AUTOSAR XML (schema 00048)
package /VehicleProject
  system System
package /Cluster
  can cluster CAN00: protocol-name=CAN  # CANFD364
    can physical channel CHNL: comm-connectors=CN_CAN00
      frame msg_MyECU_Lamp_oCAN00: id 0x511, from MyECU, frame-length=32, can-addressing-mode=STANDARD, can-frame-rx-behavior=ANY, can-frame-tx-behavior=CAN-FD  # Motor FOC diagnostic data. MotorFoc_Page selects Control (0xA0), PWM (0xA1), or ADC (0xA2) payload.
        multiplexed i pdu msg_MyECU_Lamp_oCAN00:
          length=32
          dynamic-part{segment-positions=[{segment-byte-order=little-endian, segment-length=32, segment-position=0}, {segment-byte-order=little-endian, segment-length=208, segment-position=48}], dynamic-part-alternatives=[{i-pdu=msg_MyECU_Lamp_MxA0_oCAN00, initial-dynamic-part=true, selector-field-code=160}, {i-pdu=msg_MyECU_Lamp_MxA1_oCAN00, initial-dynamic-part=false, selector-field-code=161}, {i-pdu=msg_MyECU_Lamp_MxA2_oCAN00, initial-dynamic-part=false, selector-field-code=162}]}
          selector-field-byte-order=little-endian
          selector-field-length=8
          selector-field-start-position=0
          static-part{segment-position{segment-byte-order=little-endian, segment-length=16, segment-position=32}, i-pdu=msg_MyECU_Lamp_Mx_oCAN00}
          unused-bit-pattern=0
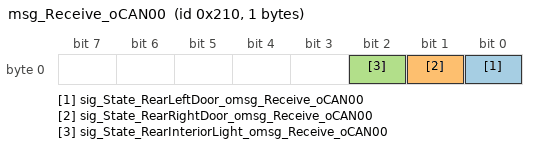
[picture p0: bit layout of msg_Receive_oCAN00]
      frame msg_Receive_oCAN00: id 0x210, to MyECU, frame-length=1, can-addressing-mode=STANDARD, can-frame-rx-behavior=ANY, can-frame-tx-behavior=CAN-20
        pdu msg_Receive_oCAN00: length=1, minimum-delay=0, transmission-mode-false-timing=cyclic-timing={time-offset=0, time-period=0.1}, transmission-mode-true-timing=cyclic-timing={time-offset=0, time-period=0.1}, unused-bit-pattern=0
          signal sig_State_RearLeftDoor_omsg_Receive_oCAN00: start 0, 1 bit, little-endian, i-signal-type=PRIMITIVE, init-value=0, base-type=boolean, compu-method=CM_sig_State_RearLeftDoor, data-constr=DC_sig_State_RearLeftDoor, transfer-property=PENDING, to MyECU
          signal sig_State_RearRightDoor_omsg_Receive_oCAN00: start 1, 1 bit, little-endian, i-signal-type=PRIMITIVE, init-value=0, base-type=boolean, compu-method=CM_sig_State_RearRightDoor, data-constr=DC_sig_State_RearRightDoor, transfer-property=PENDING, to MyECU
          signal sig_State_RearInteriorLight_omsg_Receive_oCAN00: start 2, 1 bit, little-endian, i-signal-type=PRIMITIVE, init-value=0, base-type=boolean, compu-method=CM_sig_State_RearInteriorLight, data-constr=DC_sig_State_RearInteriorLight, transfer-property=PENDING, to MyECU
      frame msg_Transmit_oCAN00: id 0x200, from MyECU, frame-length=1, can-addressing-mode=STANDARD, can-frame-rx-behavior=ANY, can-frame-tx-behavior=CAN-20
        pdu msg_Transmit_oCAN00: length=1, minimum-delay=0, transmission-mode-false-timing=cyclic-timing={time-offset=0, time-period=0.1}, transmission-mode-true-timing=cyclic-timing={time-offset=0, time-period=0.1}, unused-bit-pattern=0
          signal sig_RearInteriorLight_omsg_Transmit_oCAN00: start 0, 1 bit, little-endian, i-signal-type=PRIMITIVE, init-value=0, base-type=boolean, compu-method=CM_sig_RearInteriorLight, data-constr=DC_sig_RearInteriorLight, transfer-property=PENDING
      pdu triggering PT_msg_MyECU_Lamp_Mx: pdu=msg_MyECU_Lamp_Mx_oCAN00, from MyECU
      pdu triggering PT_msg_MyECU_Lamp_MxA{0..2}: pdu=msg_MyECU_Lamp_MxA{0..2}_oCAN00, from MyECU
package /ECU
  ecu instance MyECU: associated-com-i-pdu-group=[MyECU_oCAN00_Rx, MyECU_oCAN00_Tx]
    can communication controller CT_CAN00
    can communication connector CN_CAN00: comm-controller=CT_CAN00
package /IPDUGroup
  i signal i pdu group MyECU_oCAN00_Rx: communication-direction=IN, i-signal-i-pdus=msg_Receive_oCAN00
  i signal i pdu group MyECU_oCAN00_Tx: communication-direction=OUT
    i-signal-i-pdus:
      msg_MyECU_Lamp_Mx_oCAN00
      msg_MyECU_Lamp_MxA{0..2}_oCAN00
      msg_Transmit_oCAN00
package /PDU
  pdu msg_MyECU_Lamp_Mx_oCAN00: length=32, minimum-delay=0, transmission-mode-true-timing=event-controlled-timing={number-of-repetitions=0, repetition-period=0}, unused-bit-pattern=0
    signal MotorFoc_Sequence_Mx_omsg_MyECU_Lamp_oCAN00: start 32, 16 bit, little-endian, i-signal-type=PRIMITIVE, init-value=0, base-type=uint16, compu-method=CM_MotorFoc_Sequence, data-constr=DC_MotorFoc_Sequence, transfer-property=TRIGGERED-WITHOUT-REPETITION
  pdu msg_MyECU_Lamp_MxA0_oCAN00: length=32, minimum-delay=0, transmission-mode-true-timing=cyclic-timing={time-offset=0, time-period=0.015}, unused-bit-pattern=0
    signal MotorFoc_Page_MxA0_omsg_MyECU_Lamp_oCAN00: start 0, 8 bit, little-endian, i-signal-type=PRIMITIVE, init-value=160, base-type=uint8, compu-method=CM_MotorFoc_Page, data-constr=DC_MotorFoc_Page, transfer-property=PENDING
    signal MotorFoc_MotorMode_MxA0_omsg_MyECU_Lamp_oCAN00: start 8, 8 bit, little-endian, i-signal-type=PRIMITIVE, init-value=0, base-type=uint8, compu-method=CM_MotorFoc_MotorMode, data-constr=DC_MotorFoc_MotorMode, transfer-property=PENDING
    signal MotorFoc_Fault_MxA0_omsg_MyECU_Lamp_oCAN00: start 16, 8 bit, little-endian, i-signal-type=PRIMITIVE, init-value=0, base-type=uint8, compu-method=CM_MotorFoc_Fault, data-constr=DC_MotorFoc_Fault, transfer-property=PENDING
    signal MotorFoc_FaultReason_MxA0_omsg_MyECU_Lamp_oCAN00: start 24, 8 bit, little-endian, i-signal-type=PRIMITIVE, init-value=0, base-type=uint8, compu-method=CM_MotorFoc_FaultReason, data-constr=DC_MotorFoc_FaultReason, transfer-property=PENDING
    signal MotorFoc_IdRef_A_MxA0_omsg_MyECU_Lamp_oCAN00: start 48, 16 bit, little-endian, i-signal-type=PRIMITIVE, init-value=0, base-type=sint16, compu-method=CM_MotorFoc_IdRef_A, data-constr=DC_MotorFoc_IdRef_A, unit=U_A, transfer-property=PENDING
    signal MotorFoc_IqRef_A_MxA0_omsg_MyECU_Lamp_oCAN00: start 64, 16 bit, little-endian, i-signal-type=PRIMITIVE, init-value=0, base-type=sint16, compu-method=CM_MotorFoc_IqRef_A, data-constr=DC_MotorFoc_IqRef_A, unit=U_A, transfer-property=PENDING
    signal MotorFoc_Id_A_MxA0_omsg_MyECU_Lamp_oCAN00: start 80, 16 bit, little-endian, i-signal-type=PRIMITIVE, init-value=0, base-type=sint16, compu-method=CM_MotorFoc_Id_A, data-constr=DC_MotorFoc_Id_A, unit=U_A, transfer-property=PENDING
    signal MotorFoc_Iq_A_MxA0_omsg_MyECU_Lamp_oCAN00: start 96, 16 bit, little-endian, i-signal-type=PRIMITIVE, init-value=0, base-type=sint16, compu-method=CM_MotorFoc_Iq_A, data-constr=DC_MotorFoc_Iq_A, unit=U_A, transfer-property=PENDING
    signal MotorFoc_Iu_A_MxA0_omsg_MyECU_Lamp_oCAN00: start 112, 16 bit, little-endian, i-signal-type=PRIMITIVE, init-value=0, base-type=sint16, compu-method=CM_MotorFoc_Iu_A, data-constr=DC_MotorFoc_Iu_A, unit=U_A, transfer-property=PENDING
    signal MotorFoc_Iv_A_MxA0_omsg_MyECU_Lamp_oCAN00: start 128, 16 bit, little-endian, i-signal-type=PRIMITIVE, init-value=0, base-type=sint16, compu-method=CM_MotorFoc_Iv_A, data-constr=DC_MotorFoc_Iv_A, unit=U_A, transfer-property=PENDING
    signal MotorFoc_Iw_A_MxA0_omsg_MyECU_Lamp_oCAN00: start 144, 16 bit, little-endian, i-signal-type=PRIMITIVE, init-value=0, base-type=sint16, compu-method=CM_MotorFoc_Iw_A, data-constr=DC_MotorFoc_Iw_A, unit=U_A, transfer-property=PENDING
    signal MotorFoc_Vdc_V_MxA0_omsg_MyECU_Lamp_oCAN00: start 160, 16 bit, little-endian, i-signal-type=PRIMITIVE, init-value=0, base-type=sint16, compu-method=CM_MotorFoc_Vdc_V, data-constr=DC_MotorFoc_Vdc_V, unit=U_V, transfer-property=PENDING
    signal MotorFoc_AngleRaw_MxA0_omsg_MyECU_Lamp_oCAN00: start 176, 16 bit, little-endian, i-signal-type=PRIMITIVE, init-value=0, base-type=uint16, compu-method=CM_MotorFoc_AngleRaw, data-constr=DC_MotorFoc_AngleRaw, unit=U_count, transfer-property=PENDING
    signal MotorFoc_ElectricalAngle_rad_MxA0_omsg_MyECU_Lamp_oCAN00: start 192, 16 bit, little-endian, i-signal-type=PRIMITIVE, init-value=0, base-type=sint16, compu-method=CM_MotorFoc_ElectricalAngle_rad, data-constr=DC_MotorFoc_ElectricalAngle_rad, unit=U_rad, transfer-property=PENDING
    signal MotorFoc_CurrentOffsetReady_MxA0_omsg_MyECU_Lamp_oCAN00: start 208, 8 bit, little-endian, i-signal-type=PRIMITIVE, init-value=0, base-type=uint8, compu-method=CM_MotorFoc_CurrentOffsetReady, data-constr=DC_MotorFoc_CurrentOffsetReady, transfer-property=PENDING
    signal MotorFoc_CurrentOffsetSampleCount_MxA0_omsg_MyECU_Lamp_oCAN00: start 216, 8 bit, little-endian, i-signal-type=PRIMITIVE, init-value=0, base-type=uint8, compu-method=CM_MotorFoc_CurrentOffsetSampleCount, data-constr=DC_MotorFoc_CurrentOffsetSampleCount, unit=U_sample, transfer-property=PENDING
    signal MotorFoc_MechanicalSpeed_rpm_MxA0_omsg_MyECU_Lamp_oCAN00: start 224, 16 bit, little-endian, i-signal-type=PRIMITIVE, init-value=0, base-type=sint16, compu-method=CM_MotorFoc_MechanicalSpeed_rpm, data-constr=DC_MotorFoc_MechanicalSpeed_rpm, unit=U_rpm, transfer-property=PENDING
    signal MotorFoc_GateDriverState_MxA0_omsg_MyECU_Lamp_oCAN00: start 240, 8 bit, little-endian, i-signal-type=PRIMITIVE, init-value=0, base-type=uint8, compu-method=CM_MotorFoc_GateDriverState, data-constr=DC_MotorFoc_GateDriverState, transfer-property=PENDING
    signal MotorFoc_GateDriverOutputEnabled_MxA0_omsg_MyECU_Lamp_oCAN00: start 248, 8 bit, little-endian, i-signal-type=PRIMITIVE, init-value=0, base-type=uint8, compu-method=CM_MotorFoc_GateDriverOutputEnabled, data-constr=DC_MotorFoc_GateDriverOutputEnabled, transfer-property=PENDING
  pdu msg_MyECU_Lamp_MxA1_oCAN00: length=32, minimum-delay=0, transmission-mode-true-timing=cyclic-timing={time-offset=0.005, time-period=0.015}, unused-bit-pattern=0
    signal MotorFoc_Page_MxA1_omsg_MyECU_Lamp_oCAN00: start 0, 8 bit, little-endian, i-signal-type=PRIMITIVE, init-value=161, base-type=uint8, compu-method=CM_MotorFoc_Page, data-constr=DC_MotorFoc_Page, transfer-property=PENDING
    signal MotorFoc_MotorModePwm_MxA1_omsg_MyECU_Lamp_oCAN00: start 8, 8 bit, little-endian, i-signal-type=PRIMITIVE, init-value=0, base-type=uint8, compu-method=CM_MotorFoc_MotorModePwm, data-constr=DC_MotorFoc_MotorModePwm, transfer-property=PENDING
    signal MotorFoc_FaultPwm_MxA1_omsg_MyECU_Lamp_oCAN00: start 16, 8 bit, little-endian, i-signal-type=PRIMITIVE, init-value=0, base-type=uint8, compu-method=CM_MotorFoc_FaultPwm, data-constr=DC_MotorFoc_FaultPwm, transfer-property=PENDING
    signal MotorFoc_FaultReasonPwm_MxA1_omsg_MyECU_Lamp_oCAN00: start 24, 8 bit, little-endian, i-signal-type=PRIMITIVE, init-value=0, base-type=uint8, compu-method=CM_MotorFoc_FaultReasonPwm, data-constr=DC_MotorFoc_FaultReasonPwm, transfer-property=PENDING
    signal MotorFoc_VdRef_V_MxA1_omsg_MyECU_Lamp_oCAN00: start 48, 16 bit, little-endian, i-signal-type=PRIMITIVE, init-value=0, base-type=sint16, compu-method=CM_MotorFoc_VdRef_V, data-constr=DC_MotorFoc_VdRef_V, unit=U_V, transfer-property=PENDING
    signal MotorFoc_VqRef_V_MxA1_omsg_MyECU_Lamp_oCAN00: start 64, 16 bit, little-endian, i-signal-type=PRIMITIVE, init-value=0, base-type=sint16, compu-method=CM_MotorFoc_VqRef_V, data-constr=DC_MotorFoc_VqRef_V, unit=U_V, transfer-property=PENDING
    signal MotorFoc_ValphaRef_V_MxA1_omsg_MyECU_Lamp_oCAN00: start 80, 16 bit, little-endian, i-signal-type=PRIMITIVE, init-value=0, base-type=sint16, compu-method=CM_MotorFoc_ValphaRef_V, data-constr=DC_MotorFoc_ValphaRef_V, unit=U_V, transfer-property=PENDING
    signal MotorFoc_VbetaRef_V_MxA1_omsg_MyECU_Lamp_oCAN00: start 96, 16 bit, little-endian, i-signal-type=PRIMITIVE, init-value=0, base-type=sint16, compu-method=CM_MotorFoc_VbetaRef_V, data-constr=DC_MotorFoc_VbetaRef_V, unit=U_V, transfer-property=PENDING
    signal MotorFoc_PwmU_MxA1_omsg_MyECU_Lamp_oCAN00: start 112, 16 bit, little-endian, i-signal-type=PRIMITIVE, init-value=0, base-type=uint16, compu-method=CM_MotorFoc_PwmU, data-constr=DC_MotorFoc_PwmU, unit=U_tick, transfer-property=PENDING
    signal MotorFoc_PwmV_MxA1_omsg_MyECU_Lamp_oCAN00: start 128, 16 bit, little-endian, i-signal-type=PRIMITIVE, init-value=0, base-type=uint16, compu-method=CM_MotorFoc_PwmV, data-constr=DC_MotorFoc_PwmV, unit=U_tick, transfer-property=PENDING
    signal MotorFoc_PwmW_MxA1_omsg_MyECU_Lamp_oCAN00: start 144, 16 bit, little-endian, i-signal-type=PRIMITIVE, init-value=0, base-type=uint16, compu-method=CM_MotorFoc_PwmW, data-constr=DC_MotorFoc_PwmW, unit=U_tick, transfer-property=PENDING
    signal MotorFoc_PwmPeriod_MxA1_omsg_MyECU_Lamp_oCAN00: start 160, 16 bit, little-endian, i-signal-type=PRIMITIVE, init-value=0, base-type=uint16, compu-method=CM_MotorFoc_PwmPeriod, data-constr=DC_MotorFoc_PwmPeriod, unit=U_tick, transfer-property=PENDING
    signal MotorFoc_VdcMax_V_MxA1_omsg_MyECU_Lamp_oCAN00: start 176, 16 bit, little-endian, i-signal-type=PRIMITIVE, init-value=0, base-type=sint16, compu-method=CM_MotorFoc_VdcMax_V, data-constr=DC_MotorFoc_VdcMax_V, unit=U_V, transfer-property=PENDING
    signal MotorFoc_FaultIu_A_MxA1_omsg_MyECU_Lamp_oCAN00: start 192, 16 bit, little-endian, i-signal-type=PRIMITIVE, init-value=0, base-type=sint16, compu-method=CM_MotorFoc_FaultIu_A, data-constr=DC_MotorFoc_FaultIu_A, unit=U_A, transfer-property=PENDING
    signal MotorFoc_FaultIv_A_MxA1_omsg_MyECU_Lamp_oCAN00: start 208, 16 bit, little-endian, i-signal-type=PRIMITIVE, init-value=0, base-type=sint16, compu-method=CM_MotorFoc_FaultIv_A, data-constr=DC_MotorFoc_FaultIv_A, unit=U_A, transfer-property=PENDING
    signal MotorFoc_FaultIw_A_MxA1_omsg_MyECU_Lamp_oCAN00: start 224, 16 bit, little-endian, i-signal-type=PRIMITIVE, init-value=0, base-type=sint16, compu-method=CM_MotorFoc_FaultIw_A, data-constr=DC_MotorFoc_FaultIw_A, unit=U_A, transfer-property=PENDING
    signal MotorFoc_FaultVdc_V_MxA1_omsg_MyECU_Lamp_oCAN00: start 240, 16 bit, little-endian, i-signal-type=PRIMITIVE, init-value=0, base-type=sint16, compu-method=CM_MotorFoc_FaultVdc_V, data-constr=DC_MotorFoc_FaultVdc_V, unit=U_V, transfer-property=PENDING
  pdu msg_MyECU_Lamp_MxA2_oCAN00: length=32, minimum-delay=0, transmission-mode-true-timing=cyclic-timing={time-offset=0.01, time-period=0.015}, unused-bit-pattern=0
    signal MotorFoc_Page_MxA2_omsg_MyECU_Lamp_oCAN00: start 0, 8 bit, little-endian, i-signal-type=PRIMITIVE, init-value=162, base-type=uint8, compu-method=CM_MotorFoc_Page, data-constr=DC_MotorFoc_Page, transfer-property=PENDING
    signal MotorFoc_AdcFilterEnabled_MxA2_omsg_MyECU_Lamp_oCAN00: start 8, 8 bit, little-endian, i-signal-type=PRIMITIVE, init-value=0, base-type=uint8, compu-method=CM_MotorFoc_AdcFilterEnabled, data-constr=DC_MotorFoc_AdcFilterEnabled, transfer-property=PENDING
    signal MotorFoc_AdcFilterReady_MxA2_omsg_MyECU_Lamp_oCAN00: start 16, 8 bit, little-endian, i-signal-type=PRIMITIVE, init-value=0, base-type=uint8, compu-method=CM_MotorFoc_AdcFilterReady, data-constr=DC_MotorFoc_AdcFilterReady, transfer-property=PENDING
    signal MotorFoc_AdcFilterAlpha_MxA2_omsg_MyECU_Lamp_oCAN00: start 24, 8 bit, little-endian, i-signal-type=PRIMITIVE, init-value=0, base-type=uint8, compu-method=CM_MotorFoc_AdcFilterAlpha, data-constr=DC_MotorFoc_AdcFilterAlpha, transfer-property=PENDING
    signal MotorFoc_IuRaw_A_MxA2_omsg_MyECU_Lamp_oCAN00: start 48, 16 bit, little-endian, i-signal-type=PRIMITIVE, init-value=0, base-type=sint16, compu-method=CM_MotorFoc_IuRaw_A, data-constr=DC_MotorFoc_IuRaw_A, unit=U_A, transfer-property=PENDING
    signal MotorFoc_IvRaw_A_MxA2_omsg_MyECU_Lamp_oCAN00: start 64, 16 bit, little-endian, i-signal-type=PRIMITIVE, init-value=0, base-type=sint16, compu-method=CM_MotorFoc_IvRaw_A, data-constr=DC_MotorFoc_IvRaw_A, unit=U_A, transfer-property=PENDING
    signal MotorFoc_IwRaw_A_MxA2_omsg_MyECU_Lamp_oCAN00: start 80, 16 bit, little-endian, i-signal-type=PRIMITIVE, init-value=0, base-type=sint16, compu-method=CM_MotorFoc_IwRaw_A, data-constr=DC_MotorFoc_IwRaw_A, unit=U_A, transfer-property=PENDING
    signal MotorFoc_IuFiltered_A_MxA2_omsg_MyECU_Lamp_oCAN00: start 96, 16 bit, little-endian, i-signal-type=PRIMITIVE, init-value=0, base-type=sint16, compu-method=CM_MotorFoc_IuFiltered_A, data-constr=DC_MotorFoc_IuFiltered_A, unit=U_A, transfer-property=PENDING
    signal MotorFoc_IvFiltered_A_MxA2_omsg_MyECU_Lamp_oCAN00: start 112, 16 bit, little-endian, i-signal-type=PRIMITIVE, init-value=0, base-type=sint16, compu-method=CM_MotorFoc_IvFiltered_A, data-constr=DC_MotorFoc_IvFiltered_A, unit=U_A, transfer-property=PENDING
    signal MotorFoc_IwFiltered_A_MxA2_omsg_MyECU_Lamp_oCAN00: start 128, 16 bit, little-endian, i-signal-type=PRIMITIVE, init-value=0, base-type=sint16, compu-method=CM_MotorFoc_IwFiltered_A, data-constr=DC_MotorFoc_IwFiltered_A, unit=U_A, transfer-property=PENDING
    signal MotorFoc_AdcOffsetVo1_MxA2_omsg_MyECU_Lamp_oCAN00: start 144, 16 bit, little-endian, i-signal-type=PRIMITIVE, init-value=0, base-type=sint16, compu-method=CM_MotorFoc_AdcOffsetVo1, data-constr=DC_MotorFoc_AdcOffsetVo1, unit=U_count, transfer-property=PENDING
    signal MotorFoc_AdcOffsetVo2_MxA2_omsg_MyECU_Lamp_oCAN00: start 160, 16 bit, little-endian, i-signal-type=PRIMITIVE, init-value=0, base-type=sint16, compu-method=CM_MotorFoc_AdcOffsetVo2, data-constr=DC_MotorFoc_AdcOffsetVo2, unit=U_count, transfer-property=PENDING
    signal MotorFoc_AdcOffsetVo3_MxA2_omsg_MyECU_Lamp_oCAN00: start 176, 16 bit, little-endian, i-signal-type=PRIMITIVE, init-value=0, base-type=sint16, compu-method=CM_MotorFoc_AdcOffsetVo3, data-constr=DC_MotorFoc_AdcOffsetVo3, unit=U_count, transfer-property=PENDING
    signal MotorFoc_Vro_V_MxA2_omsg_MyECU_Lamp_oCAN00: start 192, 16 bit, little-endian, i-signal-type=PRIMITIVE, init-value=0, base-type=sint16, compu-method=CM_MotorFoc_Vro_V, data-constr=DC_MotorFoc_Vro_V, unit=U_V, transfer-property=PENDING
    signal MotorFoc_Vinv_V_MxA2_omsg_MyECU_Lamp_oCAN00: start 208, 16 bit, little-endian, i-signal-type=PRIMITIVE, init-value=0, base-type=sint16, compu-method=CM_MotorFoc_Vinv_V, data-constr=DC_MotorFoc_Vinv_V, unit=U_V, transfer-property=PENDING
    signal MotorFoc_AdcSyncCounter_MxA2_omsg_MyECU_Lamp_oCAN00: start 224, 16 bit, little-endian, i-signal-type=PRIMITIVE, init-value=0, base-type=uint16, compu-method=CM_MotorFoc_AdcSyncCounter, data-constr=DC_MotorFoc_AdcSyncCounter, unit=U_count, transfer-property=PENDING
    signal MotorFoc_AdcOffsetSampleCount_MxA2_omsg_MyECU_Lamp_oCAN00: start 240, 16 bit, little-endian, i-signal-type=PRIMITIVE, init-value=0, base-type=uint16, compu-method=CM_MotorFoc_AdcOffsetSampleCount, data-constr=DC_MotorFoc_AdcOffsetSampleCount, unit=U_sample, transfer-property=PENDING
